# APM32L07x register map
File version: 1.0
CPU: CM0+ r0p0, little endian, MPU, no FPU, 4 interrupt priority bits
Registers are 32-bit, read-write, reset 0x0 unless marked. A register's access mark holds for its fields unless they carry their own. Offsets are from the block's base; lines under a group give offsets from that group; [hi:lo] are bit positions; {n}, {i} and the like mark numbered series; 'fields as' and 'values as' point back to an identical list; <NAME> marks a mode.

## Memory map
0x40000000 TMR2 size 0x400 — General-purpose-timers
0x40000400 TMR3 size 0x400
0x40001000 TMR6 size 0x400 — Basic-timers
0x40001400 TMR7 size 0x400
0x40002400 LCD size 0x400 — Liquid crystal display controller
0x40002800 RTC size 0x400 — Real-time clock
0x40002C00 WWDT size 0x400 — Window watchdog
0x40003000 IWDT size 0x400 — Independent watchdog
0x40003800 SPI2 size 0x400
0x40004400 USART2 size 0x400
0x40004800 LPUART size 0x400 — Universal synchronous asynchronous receiver transmitter
0x40004C00 USART4 size 0x400
0x40005000 USART5 size 0x400
0x40005400 I2C1 size 0x400 — Inter-integrated circuit
0x40005800 I2C2 size 0x400
0x40006C00 CRS size 0x400 — Clock recovery system
0x40007000 PMU size 0x400 — Power control
0x40007400 DAC size 0x400 — Digital-to-analog converter
0x40007800 I2C3 size 0x400
0x40007C00 LPTMR size 0x400 — Low power timer
0x40010000 SYSCFG size 0x400 — System configuration controller
0x40010018 COMP size 0x400 — Comparator
0x40010400 EINT size 0x400 — External interrupt/event controller
0x40010800 TMR21 size 0x400 — General-purpose-timers
0x40011C00 Firewall size 0x400
0x40012400 ADC size 0x400 — Analog-to-digital converter
0x40013000 SPI1 size 0x400 — Serial peripheral interface
0x40013800 USART1 size 0x400 — Universal synchronous asynchronous receiver transmitter
0x40014400 TMR22 size 0x400 — General-purpose-timers
0x40015800 DBGMCU size 0x400 — Debug support
0x40020000 DMA size 0x400 — Direct memory access controller
0x40021000 RCM size 0x400 — Reset and clock control
0x40022000 FMC size 0x400
0x40023000 CRC size 0x400 — Cyclic redundancy check calculation unit
0x40024000 TSC size 0x400 — Touch sensing controller
0x40025000 RNG size 0x400 — Random number generator
0x40026000 AES size 0x400 — Advanced encryption standard hardware accelerator
0x50000000 GPIOA size 0x400 — General-purpose I/Os
0x50000400 GPIOB size 0x400 — General-purpose I/Os
0x50000800 GPIOC size 0x400
0x50000C00 GPIOD size 0x400
0x50001000 GPIOE size 0x400
0x50001C00 GPIOH size 0x400
0xE000E100 NVIC size 0x33D — Nested Vectored Interrupt Controller

## Interrupts
0 WWDT — Window Watchdog interrupt
1 PVD (EINT) — PVD through EXTI line detection
2 RTC — RTC interrupts
3 FLASH (FMC) — Flash global interrupt
4 RCM — RCM global interrupt
5 EINT0_1 (EINT) — EINT Line[1:0] interrupts
6 EINT2_3 (EINT) — EINT Line[3:2] interrupts
7 EINT4_15 (EINT) — EINT Line15 and EINT4 interrupts
8 TSC — Touch sensing interrupt
9 DMA_CH1 (DMA) — DMA Channel1 global interrupt
10 DMA_CH2_3 (DMA) — DMA Channel2 and 3 interrupts
11 DMA_CH4_5_6_7 (DMA) — DMA Channel4 to 7 interrupts
12 ADC_COMP (ADC) — ADC and comparator 1 and 2
13 LPTMR1 (LPTMR) — LPTMR1 interrupt through EXTI29
14 USART4_5 (USART4, USART5) — USART4 and USART5 global interrupt
15 TMR2 — TMR2 global interrupt
16 TMR3 — TMR3 global interrupt
17 TMR6_DAC (TMR6) — DAC and TMR6 interrupts
18 TMR7 — TMR7 global interrupt
20 TMR21 — TMR21 global Interrupt
22 TMR22 — TMR22 global Interrupt
23 I2C1 — I2C1 global interrupt
24 I2C2 — I2C2 global interrupt
25 SPI1 — SPI1_global_interrupt
26 SPI2 — SPI2 global interrupt
27 USART1 — USART1 global interrupt
28 USART2 — USART2 global interrupt
29 AES_RNG_LPUART1 (AES) — AES global interrupt RNG global interrupt and LPUART1 global interrupt through
30 LCD — LCD global interrupt

## AES — Advanced encryption standard hardware accelerator
Base 0x40026000
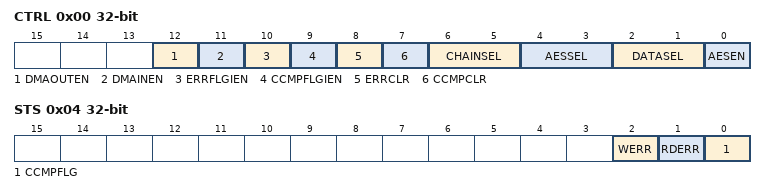
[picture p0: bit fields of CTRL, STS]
0x00 CTRL — control register
  [12] DMAOUTEN — DMA Output Enable
  [11] DMAINEN — DMA Input Enable
  [10] ERRFLGIEN — ERRFLG Interrupt Enable
  [9] CCMPFLGIEN — CCMPFLG Interrupt Enable
  [8] ERRCLR — ERRFLG Flag Bit Clear
  [7] CCMPCLR — CCMPFLG Flag Bit Clear
  [6:5] CHAINSEL — AES chaining mode
  [4:3] AESSEL — AES Operating Mode Select
  [2:1] DATASEL — Data Type Select
  [0] AESEN — AES enable
0x04 STS ro — status register
  [2] WERR — Write error flag
  [1] RDERR — Read error flag
  [0] CCMPFLG — Computation Complete Flag
0x08 DATAIN — data input register
  [31:0] DATAIN — Data Input Buffer
0x0C DATAOUT ro — data output register
  [31:0] DATAOUT — Data Output Buffer
{0x10+4i} KEY{i} (i=0..3) — key register {i}
  [31:0] KEY{i} — Cryptographic key[{32i+31}:{32i}]
{0x20+4i} INIV{i} (i=0..3) — initialization vector register {i}
  [31:0] INIV{i} — Initialization Vector Input Data[{32i+31}:{32i}]
